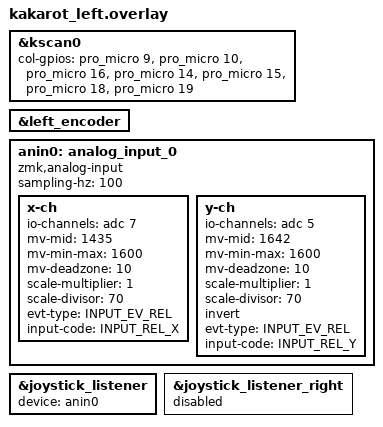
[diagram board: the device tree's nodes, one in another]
#include "kakarot.dtsi" // The shared dtsi file is included in the overlay

// Label of the kscan node in the dtsi
&kscan0 {
    col-gpios
        = <&pro_micro 9 GPIO_ACTIVE_HIGH>
        , <&pro_micro 10 GPIO_ACTIVE_HIGH>
        , <&pro_micro 16 GPIO_ACTIVE_HIGH>
        , <&pro_micro 14 GPIO_ACTIVE_HIGH>
        , <&pro_micro 15 GPIO_ACTIVE_HIGH>
        , <&pro_micro 18 GPIO_ACTIVE_HIGH>
        , <&pro_micro 19 GPIO_ACTIVE_HIGH>
        ;
};


&left_encoder {
    status = "okay";
};

anin0: analog_input_0 {
    compatible = "zmk,analog-input";
    sampling-hz = <100>;
    x-ch {
        io-channels = <&adc 7>; // <--- see ain-map.png for nRF52840
        mv-mid = <1435>;
        mv-min-max = <1600>;
        mv-deadzone = <10>;
        scale-multiplier = <1>;
        scale-divisor = <70>;
        // invert;
        evt-type = <INPUT_EV_REL>;
        input-code = <INPUT_REL_X>;
    };
    y-ch {
        io-channels = <&adc 5>; // <--- see ain-map.png for nRF52840
        mv-mid = <1642>;
        mv-min-max = <1600>;
        mv-deadzone = <10>;
        scale-multiplier = <1>;
        scale-divisor = <70>;
        invert;
        evt-type = <INPUT_EV_REL>;
        input-code = <INPUT_REL_Y>;

        /* enable report mdoe for gamepad axix or knob */
        /* to only call input_report on quantquantized value is updated */
        /* NOTE: mouse input does NOT need this */
        // report-on-change-only;

    };
};

&joystick_listener {
    status = "okay";
    device = <&anin0>;
};

&joystick_listener_right {
    status = "disabled";
};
